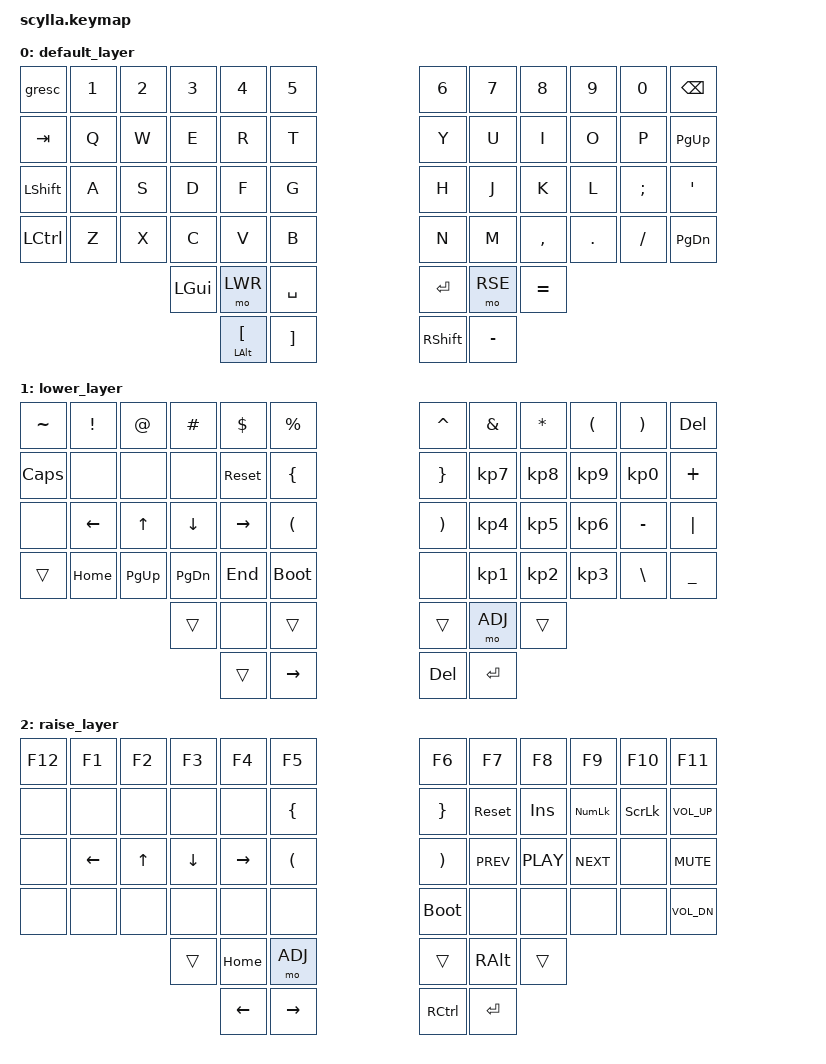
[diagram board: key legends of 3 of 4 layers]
#include <behaviors.dtsi>
#include <dt-bindings/zmk/keys.h>
#include <dt-bindings/zmk/bt.h>
#include <dt-bindings/zmk/outputs.h>
#include <dt-bindings/zmk/rgb.h>

#define DEFAULT 0
#define LWR 1
#define RSE 2
#define ADJ 3

/ {
    keymap {
        compatible = "zmk,keymap";

        default_layer {
            bindings = <
                &gresc     &kp N1  &kp N2    &kp N3    &kp N4        &kp N5                    &kp N6   &kp N7   &kp N8  &kp N9    &kp N0   &kp BSPC
                &kp TAB    &kp Q   &kp W     &kp E     &kp R         &kp T                     &kp Y    &kp U    &kp I     &kp O   &kp P    &kp PG_UP
                &kp LSHIFT &kp A   &kp S     &kp D     &kp F         &kp G                     &kp H    &kp J    &kp K     &kp L   &kp SEMI &kp SQT
                &kp LCTRL  &kp Z   &kp X     &kp C     &kp V         &kp B                     &kp N    &kp M    &kp COMMA &kp DOT &kp FSLH &kp PG_DN
                                             &kp LGUI  &mo LWR       &kp SPACE                 &kp RET  &mo RSE  &kp EQUAL
                                                       &mt LALT LBKT &kp RBKT                  &kp RSHIFT &kp MINUS
            >;
        };

        lower_layer {
            bindings = <
                &kp TILDE   &kp EXCL &kp AT    &kp HASH   &kp DLLR   &kp PRCNT            &kp CARET &kp AMPS  &kp ASTRK &kp LPAR  &kp RPAR  &kp DEL
                &kp CAPS    &none    &none     &none      &sys_reset &kp LBRC             &kp RBRC  &kp KP_N7 &kp KP_N8 &kp KP_N9 &kp KP_N0 &kp PLUS
                &none       &kp LEFT &kp UP    &kp DOWN   &kp RIGHT  &kp LPAR             &kp RPAR  &kp KP_N4 &kp KP_N5 &kp KP_N6 &kp MINUS &kp PIPE 
                &trans      &kp HOME &kp PG_UP &kp PG_DN  &kp END    &bootloader          &none     &kp KP_N1 &kp KP_N2 &kp KP_N3 &kp BSLH  &kp UNDER
                                               &trans     &none      &trans               &trans    &mo ADJ   &trans
                                                          &trans     &kp RIGHT            &kp DEL   &kp RET
            >;
        };

        raise_layer {
            bindings = <
                &kp F12 &kp F1   &kp F2          &kp F3          &kp F4          &kp F5               &kp F6      &kp F7     &kp F8     &kp F9     &kp F10  &kp F11
                &none   &none    &none           &none           &none           &kp LBRC             &kp RBRC    &sys_reset &kp INS    &kp KP_NUM &kp SLCK &kp C_VOL_UP
                &none   &kp LEFT &kp UP          &kp DOWN        &kp RIGHT       &kp LPAR             &kp RPAR    &kp C_PREV &kp C_PLAY &kp C_NEXT &none    &kp C_MUTE
                &none   &none    &none           &none           &none           &none                &bootloader &none      &none      &none      &none    &kp C_VOL_DN 
                                                 &trans          &kp HOME        &mo ADJ              &trans   &kp RALT   &trans
                                                                 &kp LEFT        &kp RIGHT            &kp RCTRL &kp RET
            >;
        };

        adjust_layer {
            bindings = <
                &out OUT_BLE &bt BT_SEL 0 &bt BT_SEL 1 &bt BT_SEL 2 &bt BT_SEL 3 &bt BT_SEL 4              &none &none &none &none &none &none
                &out OUT_USB &none        &none        &none        &sys_reset   &none                     &none &none &none &none &none &none
                &none                     &none        &none        &none        &none                     &none &none &none &none &none &none
                &bt BT_CLR   &none        &none        &none        &none        &bootloader               &none &none &none &none &none &none
                                                       &none        &none        &none                     &none &none &none
                                                                    &none        &none                     &none &none
            >;
        };
    };
};
